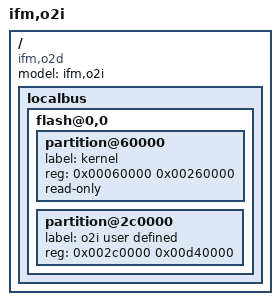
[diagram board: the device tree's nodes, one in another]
/include/ "o2d.dtsi"
/ {
	model = "ifm,o2i";
	compatible = "ifm,o2d";
	localbus {
		flash@0,0 {
			partition@60000 {
				label = "kernel";
				reg = <0x00060000 0x00260000>;
				read-only;
			};
			partition@2c0000 {
				label = "o2i user defined";
				reg = <0x002c0000 0x00d40000>;
			};
		};
	};
};
